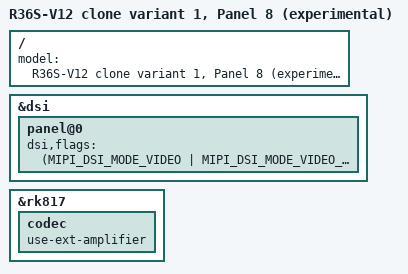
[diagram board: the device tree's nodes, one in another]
// SPDX-License-Identifier: (GPL-2.0+ OR MIT)
/*
 * EXPERIMENTAL - keep a copy of the files you replace so you can go back.
 *
 * EE clone "R36S-V12 2023-08-18 Variant 1 Panel 8 A": G80 wiring and Panel 8,
 * but the panel needs a continuous DSI clock. With the G80 flags (clock may
 * stop between frames) one of these boards started with a garbled or no picture.
 * Tested on two V12 clones by an andr36oid user (2026-10-12). The speaker
 * runs through an external amplifier, as in southoz's DTB; without it the
 * speaker stays silent.
 * Source: dArkOSRE port by southoz (dArkOSRE-R36, clone/R36S-V12 ... Variant 1 Panel 8 A).
 */

/dts-v1/;
#include "rk3326-r36s-clone-ee.dtsi"
#include "rk3326-r36s-clone-panel8.dtsi"

/ {
	model = "R36S-V12 clone variant 1, Panel 8 (experimental)";
};

&dsi {
	panel@0 {
		dsi,flags = <(MIPI_DSI_MODE_VIDEO |
		      MIPI_DSI_MODE_VIDEO_BURST |
		      MIPI_DSI_MODE_EOT_PACKET |
		      MIPI_DSI_MODE_LPM)>;
	};
};

/* the speaker runs through an external amplifier (stock "use-ext-amplifier") */
&rk817 {
	codec {
		use-ext-amplifier;
	};
};
